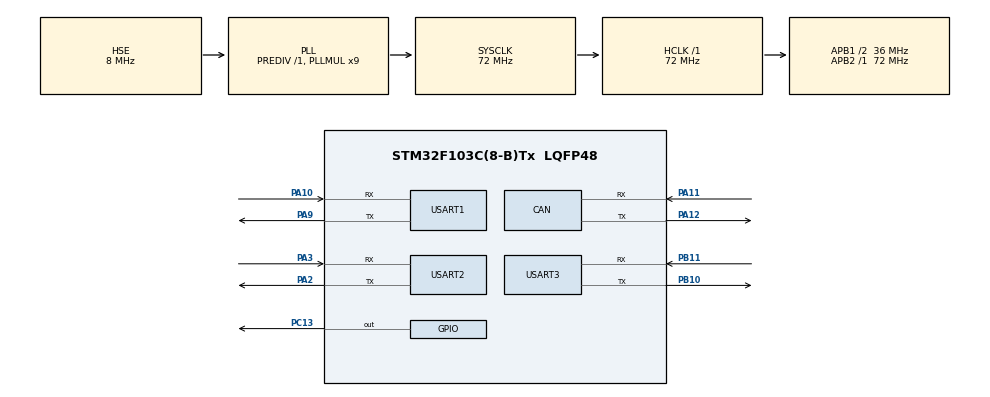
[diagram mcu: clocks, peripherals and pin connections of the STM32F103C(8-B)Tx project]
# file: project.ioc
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CAN.CalculateTimeBit=1333
CAN.CalculateTimeQuantum=444.44444444444446
Dma.Request0=USART1_RX
Dma.Request1=USART1_TX
Dma.Request2=USART2_RX
Dma.Request3=USART2_TX
Dma.Request4=USART3_RX
Dma.Request5=USART3_TX
Dma.USART1_RX.0.Direction=DMA_PERIPH_TO_MEMORY
Dma.USART1_RX.0.Instance=DMA1_Channel5
Dma.USART1_RX.0.MemDataAlignment=DMA_MDATAALIGN_BYTE
Dma.USART1_RX.0.MemInc=DMA_MINC_ENABLE
Dma.USART1_RX.0.Mode=DMA_CIRCULAR
Dma.USART1_RX.0.PeriphDataAlignment=DMA_PDATAALIGN_BYTE
Dma.USART1_RX.0.PeriphInc=DMA_PINC_DISABLE
Dma.USART1_RX.0.Priority=DMA_PRIORITY_LOW
Dma.USART1_TX.1.Direction=DMA_MEMORY_TO_PERIPH
Dma.USART1_TX.1.Instance=DMA1_Channel4
Dma.USART1_TX.1.MemDataAlignment=DMA_MDATAALIGN_BYTE
Dma.USART1_TX.1.MemInc=DMA_MINC_ENABLE
Dma.USART1_TX.1.Mode=DMA_NORMAL
Dma.USART1_TX.1.PeriphDataAlignment=DMA_PDATAALIGN_BYTE
Dma.USART1_TX.1.PeriphInc=DMA_PINC_DISABLE
Dma.USART1_TX.1.Priority=DMA_PRIORITY_LOW
Dma.USART2_RX.2.Direction=DMA_PERIPH_TO_MEMORY
Dma.USART2_RX.2.Instance=DMA1_Channel6
Dma.USART2_RX.2.MemDataAlignment=DMA_MDATAALIGN_BYTE
Dma.USART2_RX.2.MemInc=DMA_MINC_ENABLE
Dma.USART2_RX.2.Mode=DMA_CIRCULAR
Dma.USART2_RX.2.PeriphDataAlignment=DMA_PDATAALIGN_BYTE
Dma.USART2_RX.2.PeriphInc=DMA_PINC_DISABLE
Dma.USART2_RX.2.Priority=DMA_PRIORITY_LOW
Dma.USART2_TX.3.Direction=DMA_MEMORY_TO_PERIPH
Dma.USART2_TX.3.Instance=DMA1_Channel7
Dma.USART2_TX.3.MemDataAlignment=DMA_MDATAALIGN_BYTE
Dma.USART2_TX.3.MemInc=DMA_MINC_ENABLE
Dma.USART2_TX.3.Mode=DMA_NORMAL
Dma.USART2_TX.3.PeriphDataAlignment=DMA_PDATAALIGN_BYTE
Dma.USART2_TX.3.PeriphInc=DMA_PINC_DISABLE
Dma.USART2_TX.3.Priority=DMA_PRIORITY_LOW
Dma.USART3_RX.4.Direction=DMA_PERIPH_TO_MEMORY
Dma.USART3_RX.4.Instance=DMA1_Channel3
Dma.USART3_RX.4.MemDataAlignment=DMA_MDATAALIGN_BYTE
Dma.USART3_RX.4.MemInc=DMA_MINC_ENABLE
Dma.USART3_RX.4.Mode=DMA_CIRCULAR
Dma.USART3_RX.4.PeriphDataAlignment=DMA_PDATAALIGN_BYTE
Dma.USART3_RX.4.PeriphInc=DMA_PINC_DISABLE
Dma.USART3_RX.4.Priority=DMA_PRIORITY_LOW
Dma.USART3_TX.5.Direction=DMA_MEMORY_TO_PERIPH
Dma.USART3_TX.5.Instance=DMA1_Channel2
Dma.USART3_TX.5.MemDataAlignment=DMA_MDATAALIGN_BYTE
Dma.USART3_TX.5.MemInc=DMA_MINC_ENABLE
Dma.USART3_TX.5.Mode=DMA_NORMAL
Dma.USART3_TX.5.PeriphDataAlignment=DMA_PDATAALIGN_BYTE
Dma.USART3_TX.5.PeriphInc=DMA_PINC_DISABLE
Dma.USART3_TX.5.Priority=DMA_PRIORITY_LOW
FREERTOS.Tasks01=defaultTask,24,128,StartDefaultTask,Default,NULL,Dynamic,NULL,NULL
FREERTOS.configGENERATE_RUN_TIME_STATS=0
FREERTOS.configTOTAL_HEAP_SIZE=1024 * 10
FREERTOS.configUSE_STATS_FORMATTING_FUNCTIONS=0
Mcu.Family=STM32F1
Mcu.Name=STM32F103C(8-B)Tx
Mcu.Package=LQFP48
NVIC.DMA1_Channel2_IRQn=true\:5\:0\:true\:false\:true\:true\:false\:true
NVIC.DMA1_Channel3_IRQn=true\:5\:0\:true\:false\:true\:true\:false\:true
NVIC.DMA1_Channel4_IRQn=true\:5\:0\:true\:false\:true\:true\:false\:true
NVIC.DMA1_Channel5_IRQn=true\:5\:0\:true\:false\:true\:true\:false\:true
NVIC.DMA1_Channel6_IRQn=true\:5\:0\:true\:false\:true\:true\:false\:true
NVIC.DMA1_Channel7_IRQn=true\:5\:0\:true\:false\:true\:true\:false\:true
NVIC.PriorityGroup=NVIC_PRIORITYGROUP_4
NVIC.TIM1_UP_IRQn=true\:0\:0\:false\:false\:true\:false\:false\:true
NVIC.TimeBase=TIM1_UP_IRQn
NVIC.TimeBaseIP=TIM1
NVIC.USART1_IRQn=true\:5\:0\:true\:false\:true\:false\:true\:true
NVIC.USART2_IRQn=true\:5\:0\:true\:false\:true\:true\:true\:true
NVIC.USART3_IRQn=true\:5\:0\:true\:false\:true\:true\:true\:true
NVIC.USB_LP_CAN1_RX0_IRQn=true\:5\:0\:true\:false\:true\:true\:true\:true
PA10.Mode=Asynchronous
PA10.Signal=USART1_RX
PA11.Mode=Master
PA11.Signal=CAN_RX
PA12.Mode=Master
PA12.Signal=CAN_TX
PA13.Mode=Serial_Wire
PA13.Signal=SYS_JTMS-SWDIO
PA14.Mode=Serial_Wire
PA14.Signal=SYS_JTCK-SWCLK
PA2.Mode=Asynchronous
PA2.Signal=USART2_TX
PA3.Mode=Asynchronous
PA3.Signal=USART2_RX
PA9.Mode=Asynchronous
PA9.Signal=USART1_TX
PB10.Mode=Asynchronous
PB10.Signal=USART3_TX
PB11.Mode=Asynchronous
PB11.Signal=USART3_RX
PC13-TAMPER-RTC.Signal=GPIO_Output
PD0-OSC_IN.Mode=HSE-External-Oscillator
PD0-OSC_IN.Signal=RCC_OSC_IN
PD1-OSC_OUT.Mode=HSE-External-Oscillator
PD1-OSC_OUT.Signal=RCC_OSC_OUT
ProjectManager.HeapSize=0x600
ProjectManager.StackSize=0x400
ProjectManager.TargetToolchain=Makefile
RCC.AHBFreq_Value=72000000
RCC.APB1CLKDivider=RCC_HCLK_DIV2
RCC.APB1Freq_Value=36000000
RCC.APB1TimFreq_Value=72000000
RCC.APB2Freq_Value=72000000
RCC.APB2TimFreq_Value=72000000
RCC.HCLKFreq_Value=72000000
RCC.PLLMUL=RCC_PLL_MUL9
RCC.PLLSourceVirtual=RCC_PLLSOURCE_HSE
RCC.SYSCLKFreq_VALUE=72000000
RCC.SYSCLKSource=RCC_SYSCLKSOURCE_PLLCLK
RCC.USBFreq_Value=72000000
USART1.VirtualMode=VM_ASYNC
USART2.VirtualMode=VM_ASYNC
USART3.VirtualMode=VM_ASYNC
VP_FREERTOS_VS_CMSIS_V2.Mode=CMSIS_V2
VP_SYS_VS_tim1.Mode=TIM1
board=custom

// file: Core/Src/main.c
/* USER CODE BEGIN Header */
/**
  ******************************************************************************
  * @file           : main.c
  * @brief          : Main program body
  ******************************************************************************
  * @attention
  *
  * <h2><center>&copy; Copyright (c) 2020 STMicroelectronics.
  * All rights reserved.</center></h2>
  *
  * This software component is licensed by ST under Ultimate Liberty license
  * SLA0044, the "License"; You may not use this file except in compliance with
  * the License. You may obtain a copy of the License at:
  *                             www.st.com/SLA0044
  *
  ******************************************************************************
  */
/* USER CODE END Header */
#include "main.h"
#include "cmsis_os.h"

/* USER CODE BEGIN Includes */
int abc=0;
/* USER CODE END Includes */

CAN_HandleTypeDef hcan;

UART_HandleTypeDef huart1;
UART_HandleTypeDef huart2;
UART_HandleTypeDef huart3;
DMA_HandleTypeDef hdma_usart1_rx;
DMA_HandleTypeDef hdma_usart1_tx;
DMA_HandleTypeDef hdma_usart2_rx;
DMA_HandleTypeDef hdma_usart2_tx;
DMA_HandleTypeDef hdma_usart3_rx;
DMA_HandleTypeDef hdma_usart3_tx;

/* Definitions for defaultTask */
osThreadId_t defaultTaskHandle;
const osThreadAttr_t defaultTask_attributes = {
  .name = "defaultTask",
  .priority = (osPriority_t) osPriorityNormal,
  .stack_size = 128 * 4
};

void SystemClock_Config(void);
static void MX_GPIO_Init(void);
static void MX_DMA_Init(void);
static void MX_USART1_UART_Init(void);
static void MX_USART2_UART_Init(void);
static void MX_USART3_UART_Init(void);
static void MX_CAN_Init(void);
void StartDefaultTask(void *argument);

int main(void)
{

  /* MCU Configuration--------------------------------------------------------*/

  /* Reset of all peripherals, Initializes the Flash interface and the Systick. */
  HAL_Init();

  /* Configure the system clock */
  SystemClock_Config();

  /* Initialize all configured peripherals */
  MX_GPIO_Init();
  MX_DMA_Init();
  MX_USART1_UART_Init();
  MX_USART2_UART_Init();
  MX_USART3_UART_Init();
  MX_CAN_Init();

  /* Init scheduler */
  osKernelInitialize();

  /* Create the thread(s) */
  /* creation of defaultTask */
  defaultTaskHandle = osThreadNew(StartDefaultTask, NULL, &defaultTask_attributes);

  /* USER CODE BEGIN RTOS_THREADS */
  /* add threads, ... */
  extern void defaultTaskStart();
  defaultTaskStart();
  /* USER CODE END RTOS_THREADS */

  /* Start scheduler */
  osKernelStart();

  /* We should never get here as control is now taken by the scheduler */
  /* Infinite loop */
  while (1)
  {

  }
}

void SystemClock_Config(void)
{
  RCC_OscInitTypeDef RCC_OscInitStruct = {0};
  RCC_ClkInitTypeDef RCC_ClkInitStruct = {0};

  /** Initializes the RCC Oscillators according to the specified parameters
  * in the RCC_OscInitTypeDef structure.
  */
  RCC_OscInitStruct.OscillatorType = RCC_OSCILLATORTYPE_HSE;
  RCC_OscInitStruct.HSEState = RCC_HSE_ON;
  RCC_OscInitStruct.HSEPredivValue = RCC_HSE_PREDIV_DIV1;
  RCC_OscInitStruct.HSIState = RCC_HSI_ON;
  RCC_OscInitStruct.PLL.PLLState = RCC_PLL_ON;
  RCC_OscInitStruct.PLL.PLLSource = RCC_PLLSOURCE_HSE;
  RCC_OscInitStruct.PLL.PLLMUL = RCC_PLL_MUL9;
  if (HAL_RCC_OscConfig(&RCC_OscInitStruct) != HAL_OK)
  {
    Error_Handler();
  }
  /** Initializes the CPU, AHB and APB buses clocks
  */
  RCC_ClkInitStruct.ClockType = RCC_CLOCKTYPE_HCLK|RCC_CLOCKTYPE_SYSCLK
                              |RCC_CLOCKTYPE_PCLK1|RCC_CLOCKTYPE_PCLK2;
  RCC_ClkInitStruct.SYSCLKSource = RCC_SYSCLKSOURCE_PLLCLK;
  RCC_ClkInitStruct.AHBCLKDivider = RCC_SYSCLK_DIV1;
  RCC_ClkInitStruct.APB1CLKDivider = RCC_HCLK_DIV2;
  RCC_ClkInitStruct.APB2CLKDivider = RCC_HCLK_DIV1;

  if (HAL_RCC_ClockConfig(&RCC_ClkInitStruct, FLASH_LATENCY_2) != HAL_OK)
  {
    Error_Handler();
  }
}

static void MX_CAN_Init(void)
{

  hcan.Instance = CAN1;
  hcan.Init.Prescaler = 16;
  hcan.Init.Mode = CAN_MODE_NORMAL;
  hcan.Init.SyncJumpWidth = CAN_SJW_1TQ;
  hcan.Init.TimeSeg1 = CAN_BS1_1TQ;
  hcan.Init.TimeSeg2 = CAN_BS2_1TQ;
  hcan.Init.TimeTriggeredMode = DISABLE;
  hcan.Init.AutoBusOff = DISABLE;
  hcan.Init.AutoWakeUp = DISABLE;
  hcan.Init.AutoRetransmission = DISABLE;
  hcan.Init.ReceiveFifoLocked = DISABLE;
  hcan.Init.TransmitFifoPriority = DISABLE;
  if (HAL_CAN_Init(&hcan) != HAL_OK)
  {
    Error_Handler();
  }

}

static void MX_USART1_UART_Init(void)
{

  huart1.Instance = USART1;
  huart1.Init.BaudRate = 115200;
  huart1.Init.WordLength = UART_WORDLENGTH_8B;
  huart1.Init.StopBits = UART_STOPBITS_1;
  huart1.Init.Parity = UART_PARITY_NONE;
  huart1.Init.Mode = UART_MODE_TX_RX;
  huart1.Init.HwFlowCtl = UART_HWCONTROL_NONE;
  huart1.Init.OverSampling = UART_OVERSAMPLING_16;
  if (HAL_UART_Init(&huart1) != HAL_OK)
  {
    Error_Handler();
  }

}

static void MX_USART2_UART_Init(void)
{

  huart2.Instance = USART2;
  huart2.Init.BaudRate = 115200;
  huart2.Init.WordLength = UART_WORDLENGTH_8B;
  huart2.Init.StopBits = UART_STOPBITS_1;
  huart2.Init.Parity = UART_PARITY_NONE;
  huart2.Init.Mode = UART_MODE_TX_RX;
  huart2.Init.HwFlowCtl = UART_HWCONTROL_NONE;
  huart2.Init.OverSampling = UART_OVERSAMPLING_16;
  if (HAL_UART_Init(&huart2) != HAL_OK)
  {
    Error_Handler();
  }

}

static void MX_USART3_UART_Init(void)
{

  huart3.Instance = USART3;
  huart3.Init.BaudRate = 115200;
  huart3.Init.WordLength = UART_WORDLENGTH_8B;
  huart3.Init.StopBits = UART_STOPBITS_1;
  huart3.Init.Parity = UART_PARITY_NONE;
  huart3.Init.Mode = UART_MODE_TX_RX;
  huart3.Init.HwFlowCtl = UART_HWCONTROL_NONE;
  huart3.Init.OverSampling = UART_OVERSAMPLING_16;
  if (HAL_UART_Init(&huart3) != HAL_OK)
  {
    Error_Handler();
  }

}

static void MX_DMA_Init(void)
{

  /* DMA controller clock enable */
  __HAL_RCC_DMA1_CLK_ENABLE();

  /* DMA interrupt init */
  /* DMA1_Channel2_IRQn interrupt configuration */
  HAL_NVIC_SetPriority(DMA1_Channel2_IRQn, 5, 0);
  HAL_NVIC_EnableIRQ(DMA1_Channel2_IRQn);
  /* DMA1_Channel3_IRQn interrupt configuration */
  HAL_NVIC_SetPriority(DMA1_Channel3_IRQn, 5, 0);
  HAL_NVIC_EnableIRQ(DMA1_Channel3_IRQn);
  /* DMA1_Channel4_IRQn interrupt configuration */
  HAL_NVIC_SetPriority(DMA1_Channel4_IRQn, 5, 0);
  HAL_NVIC_EnableIRQ(DMA1_Channel4_IRQn);
  /* DMA1_Channel5_IRQn interrupt configuration */
  HAL_NVIC_SetPriority(DMA1_Channel5_IRQn, 5, 0);
  HAL_NVIC_EnableIRQ(DMA1_Channel5_IRQn);
  /* DMA1_Channel6_IRQn interrupt configuration */
  HAL_NVIC_SetPriority(DMA1_Channel6_IRQn, 5, 0);
  HAL_NVIC_EnableIRQ(DMA1_Channel6_IRQn);
  /* DMA1_Channel7_IRQn interrupt configuration */
  HAL_NVIC_SetPriority(DMA1_Channel7_IRQn, 5, 0);
  HAL_NVIC_EnableIRQ(DMA1_Channel7_IRQn);

}

static void MX_GPIO_Init(void)
{
  GPIO_InitTypeDef GPIO_InitStruct = {0};

  /* GPIO Ports Clock Enable */
  __HAL_RCC_GPIOC_CLK_ENABLE();
  __HAL_RCC_GPIOD_CLK_ENABLE();
  __HAL_RCC_GPIOA_CLK_ENABLE();
  __HAL_RCC_GPIOB_CLK_ENABLE();

  /*Configure GPIO pin Output Level */
  HAL_GPIO_WritePin(GPIOC, GPIO_PIN_13, GPIO_PIN_RESET);

  /*Configure GPIO pin : PC13 */
  GPIO_InitStruct.Pin = GPIO_PIN_13;
  GPIO_InitStruct.Mode = GPIO_MODE_OUTPUT_PP;
  GPIO_InitStruct.Pull = GPIO_NOPULL;
  GPIO_InitStruct.Speed = GPIO_SPEED_FREQ_LOW;
  HAL_GPIO_Init(GPIOC, &GPIO_InitStruct);

  /*Configure GPIO pins : PC14 PC15 */
  GPIO_InitStruct.Pin = GPIO_PIN_14|GPIO_PIN_15;
  GPIO_InitStruct.Mode = GPIO_MODE_ANALOG;
  HAL_GPIO_Init(GPIOC, &GPIO_InitStruct);

  /*Configure GPIO pins : PA0 PA1 PA4 PA5
                           PA6 PA7 PA8 PA15 */
  GPIO_InitStruct.Pin = GPIO_PIN_0|GPIO_PIN_1|GPIO_PIN_4|GPIO_PIN_5
                          |GPIO_PIN_6|GPIO_PIN_7|GPIO_PIN_8|GPIO_PIN_15;
  GPIO_InitStruct.Mode = GPIO_MODE_ANALOG;
  HAL_GPIO_Init(GPIOA, &GPIO_InitStruct);

  /*Configure GPIO pins : PB0 PB1 PB2 PB12
                           PB13 PB14 PB15 PB3
                           PB4 PB5 PB6 PB7
                           PB8 PB9 */
  GPIO_InitStruct.Pin = GPIO_PIN_0|GPIO_PIN_1|GPIO_PIN_2|GPIO_PIN_12
                          |GPIO_PIN_13|GPIO_PIN_14|GPIO_PIN_15|GPIO_PIN_3
                          |GPIO_PIN_4|GPIO_PIN_5|GPIO_PIN_6|GPIO_PIN_7
                          |GPIO_PIN_8|GPIO_PIN_9;
  GPIO_InitStruct.Mode = GPIO_MODE_ANALOG;
  HAL_GPIO_Init(GPIOB, &GPIO_InitStruct);

}

void StartDefaultTask(void *argument)
{
  for(;;)
  {
    osDelay(1);
  }
}

void HAL_TIM_PeriodElapsedCallback(TIM_HandleTypeDef *htim)
{
  if (htim->Instance == TIM1) {
    HAL_IncTick();
  }
}

void Error_Handler(void)
{
}

/************************ (C) COPYRIGHT STMicroelectronics *****END OF FILE****/
